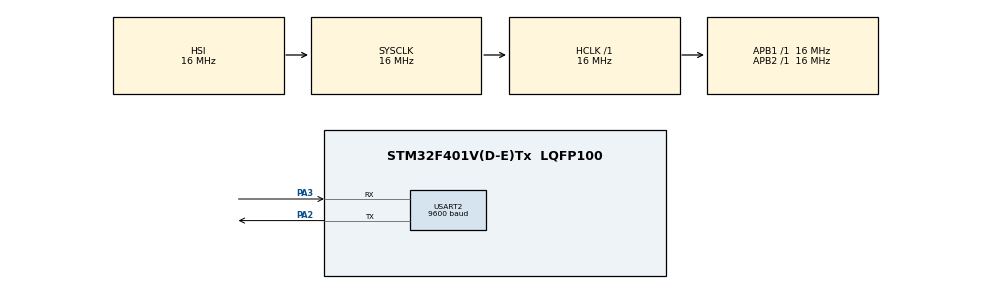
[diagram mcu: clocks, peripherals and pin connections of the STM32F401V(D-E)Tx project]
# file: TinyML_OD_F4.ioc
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Mcu.Family=STM32F4
Mcu.Name=STM32F401V(D-E)Tx
Mcu.Package=LQFP100
NVIC.PriorityGroup=NVIC_PRIORITYGROUP_4
NVIC.USART2_IRQn=true\:0\:0\:false\:false\:true\:true\:true\:true
PA13.Mode=Serial_Wire
PA13.Signal=SYS_JTMS-SWDIO
PA14.Mode=Serial_Wire
PA14.Signal=SYS_JTCK-SWCLK
PA2.Mode=Asynchronous
PA2.Signal=USART2_TX
PA3.Mode=Asynchronous
PA3.Signal=USART2_RX
ProjectManager.HeapSize=0x4000
ProjectManager.StackSize=0x2000
ProjectManager.TargetToolchain=MDK-ARM V5.32
RCC.48MHZClocksFreq_Value=32000000
RCC.AHBFreq_Value=16000000
RCC.APB1Freq_Value=16000000
RCC.APB1TimFreq_Value=16000000
RCC.APB2Freq_Value=16000000
RCC.APB2TimFreq_Value=16000000
RCC.CortexFreq_Value=16000000
RCC.HCLKFreq_Value=16000000
RCC.HSE_VALUE=25000000
RCC.HSI_VALUE=16000000
RCC.LSE_VALUE=32768
RCC.PLLM=8
RCC.PLLN=64
RCC.SYSCLKFreq_VALUE=16000000
RCC.VCOOutputFreq_Value=128000000
STMicroelectronics.X-CUBE-AI.10.0.0.ActivationBufferSizeList=45016
STMicroelectronics.X-CUBE-AI.10.0.0.ActivationBuffers=pool0
STMicroelectronics.X-CUBE-AI.10.0.0.ActivationNames=pool0
STMicroelectronics.X-CUBE-AI.10.0.0.ActivationSizes=AI_OB_MODEL_DATA_ACTIVATION_1_SIZE
STMicroelectronics.X-CUBE-AI.10.0.0.HeapSize=0x4000
STMicroelectronics.X-CUBE-AI.10.0.0.InternalRamActivationBufferMaxSize=AI_OB_MODEL_DATA_ACTIVATIONS_SIZE
STMicroelectronics.X-CUBE-AI.10.0.0.LatestDirectoryUsed-fb2fbbf6d10c69e260894ae3618b915720636bb1a9a1eeecbf556834b52556cf=D\:\\CreateProject\\TinyML_Obstacle Detection\\Ai_Model
STMicroelectronics.X-CUBE-AI.10.0.0.MaximumNumberOfInputLayer=1
STMicroelectronics.X-CUBE-AI.10.0.0.MaximumNumberOfOutputLayer=1
STMicroelectronics.X-CUBE-AI.10.0.0.MaximumSizeOfInputLayer=1
STMicroelectronics.X-CUBE-AI.10.0.0.MaximumSizeOfOutputLayer=1
STMicroelectronics.X-CUBE-AI.10.0.0.ModelActualCompression-fb2fbbf6d10c69e260894ae3618b915720636bb1a9a1eeecbf556834b52556cf=0.0
STMicroelectronics.X-CUBE-AI.10.0.0.ModelCompression-fb2fbbf6d10c69e260894ae3618b915720636bb1a9a1eeecbf556834b52556cf=High
STMicroelectronics.X-CUBE-AI.10.0.0.ModelFlashOccupation-fb2fbbf6d10c69e260894ae3618b915720636bb1a9a1eeecbf556834b52556cf=23744
STMicroelectronics.X-CUBE-AI.10.0.0.ModelHashList=fb2fbbf6d10c69e260894ae3618b915720636bb1a9a1eeecbf556834b52556cf
STMicroelectronics.X-CUBE-AI.10.0.0.ModelKind-fb2fbbf6d10c69e260894ae3618b915720636bb1a9a1eeecbf556834b52556cf=ONNX
STMicroelectronics.X-CUBE-AI.10.0.0.ModelMacc-fb2fbbf6d10c69e260894ae3618b915720636bb1a9a1eeecbf556834b52556cf=296155
STMicroelectronics.X-CUBE-AI.10.0.0.ModelName-fb2fbbf6d10c69e260894ae3618b915720636bb1a9a1eeecbf556834b52556cf=ob_model
STMicroelectronics.X-CUBE-AI.10.0.0.ModelNameList=ob_model
STMicroelectronics.X-CUBE-AI.10.0.0.ModelRamOccupation-fb2fbbf6d10c69e260894ae3618b915720636bb1a9a1eeecbf556834b52556cf=45016
STMicroelectronics.X-CUBE-AI.10.0.0.ModelStructureFile-fb2fbbf6d10c69e260894ae3618b915720636bb1a9a1eeecbf556834b52556cf=D\:\\CreateProject\\TinyML_Obstacle Detection\\Ai_Model\\obstacle_model.onnx
STMicroelectronics.X-CUBE-AI.10.0.0.ModelType-fb2fbbf6d10c69e260894ae3618b915720636bb1a9a1eeecbf556834b52556cf=STM32Cube.AI MCU runtime
STMicroelectronics.X-CUBE-AI.10.0.0.ReadyForCodeGeneration=true
STMicroelectronics.X-CUBE-AI.10.0.0.StackSize=0x2000
STMicroelectronics.X-CUBE-AI.10.0.0.WorkingBufferStartAddrList=0xFFFFFFFF
STMicroelectronics.X-CUBE-AI.10.0.0.XAaCUBEAaAICcArtificialOoIntelligenceJjCore=true
STMicroelectronics.X-CUBE-AI.10.0.0.copyWeightToRam-fb2fbbf6d10c69e260894ae3618b915720636bb1a9a1eeecbf556834b52556cf=false
STMicroelectronics.X-CUBE-AI.10.0.0.customLayerConfigEnabled-fb2fbbf6d10c69e260894ae3618b915720636bb1a9a1eeecbf556834b52556cf=false
STMicroelectronics.X-CUBE-AI.10.0.0.noOnnxIoTranspose-fb2fbbf6d10c69e260894ae3618b915720636bb1a9a1eeecbf556834b52556cf=false
STMicroelectronics.X-CUBE-AI.10.0.0.optimization-fb2fbbf6d10c69e260894ae3618b915720636bb1a9a1eeecbf556834b52556cf=ram
STMicroelectronics.X-CUBE-AI.10.0.0.useInputAllocation-fb2fbbf6d10c69e260894ae3618b915720636bb1a9a1eeecbf556834b52556cf=true
STMicroelectronics.X-CUBE-AI.10.0.0.useOutputAllocation-fb2fbbf6d10c69e260894ae3618b915720636bb1a9a1eeecbf556834b52556cf=true
USART2.BaudRate=9600
USART2.VirtualMode=VM_ASYNC
VP_CRC_VS_CRC.Mode=CRC_Activate
VP_STMicroelectronics.X-CUBE-AI_VS_ArtificialOoIntelligenceJjXAaCUBEAaAI_10.0.0.Mode=ArtificialOoIntelligenceJjXAaCUBEAaAI
board=custom

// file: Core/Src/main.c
/* USER CODE BEGIN Header */
/**
  ******************************************************************************
  * @file           : main.c
  * @brief          : Main program body
  ******************************************************************************
  * @attention
  *
  * Copyright (c) 2026 STMicroelectronics.
  * All rights reserved.
  *
  * This software is licensed under terms that can be found in the LICENSE file
  * in the root directory of this software component.
  * If no LICENSE file comes with this software, it is provided AS-IS.
  *
  ******************************************************************************
  */
/* USER CODE END Header */
#include "main.h"
#include "crc.h"
#include "usart.h"
#include "gpio.h"

/* USER CODE BEGIN Includes */
#include "infer_engine.h"
#include "risk_calc.h"
#include "fsm_controller.h"
#include "sensor_sim.h"
#include <stdio.h>
#include <string.h>
/* USER CODE END Includes */

void SystemClock_Config(void);

/* USER CODE BEGIN 0 */
#define TX_BUFFER_SIZE 300
char tx_buffer[TX_BUFFER_SIZE];
volatile uint8_t tx_flag = 1;

VehicleState_t my_vehicle_state = {0};
uint8_t probability = 0;
uint8_t live_camera_frame[9216];
extern char result_buffer[200];
/* USER CODE END 0 */

int main(void)
{

  /* MCU Configuration--------------------------------------------------------*/

  /* Reset of all peripherals, Initializes the Flash interface and the Systick. */
  HAL_Init();

  /* Configure the system clock */
  SystemClock_Config();

  /* Initialize all configured peripherals */
  MX_GPIO_Init();
  MX_USART2_UART_Init();
  MX_CRC_Init();
  /* USER CODE BEGIN 2 */

  FSM_Init();

  if (InferEngine_Init())
  {
      char err_msg[] = "AI Engine Init Failed!\r\n";
      HAL_UART_Transmit(&huart2, (uint8_t*)err_msg, strlen(err_msg), HAL_MAX_DELAY);
      Error_Handler();
  }

  /* USER CODE END 2 */

  /* Infinite loop */
  /* USER CODE BEGIN WHILE */

  while (1)
  {

		uint8_t prob = SensorSim_CaptureDynamicFrame(live_camera_frame);
		probability = prob;

		FSM_Update(probability, &my_vehicle_state);

		if (tx_flag)
    {
        tx_flag = 0;

				int offset = 0;

				if (result_buffer[0] != '\0')
        {
            offset += snprintf(tx_buffer + offset,
                                (size_t)(TX_BUFFER_SIZE - offset),
                                 "%s", result_buffer);
            if (offset < 0 || offset >= TX_BUFFER_SIZE)
            {
                offset = TX_BUFFER_SIZE - 1;
            }

            result_buffer[0] = '\0';
         }

         offset += snprintf(tx_buffer + offset,
                             (size_t)(TX_BUFFER_SIZE - offset),
                             "Prob: %d%% | TTC: %lu ms | State: %d\r\n",
                             probability,
                             (unsigned long)my_vehicle_state.ttc_ms,
                             FSM_GetState());

        HAL_UART_Transmit_IT(&huart2, (uint8_t*)tx_buffer, strlen(tx_buffer));
    }
		HAL_Delay(1500);

    /* USER CODE END WHILE */

  }
}

void SystemClock_Config(void)
{
  RCC_OscInitTypeDef RCC_OscInitStruct = {0};
  RCC_ClkInitTypeDef RCC_ClkInitStruct = {0};

  /** Configure the main internal regulator output voltage
  */
  __HAL_RCC_PWR_CLK_ENABLE();
  __HAL_PWR_VOLTAGESCALING_CONFIG(PWR_REGULATOR_VOLTAGE_SCALE2);

  /** Initializes the RCC Oscillators according to the specified parameters
  * in the RCC_OscInitTypeDef structure.
  */
  RCC_OscInitStruct.OscillatorType = RCC_OSCILLATORTYPE_HSI;
  RCC_OscInitStruct.HSIState = RCC_HSI_ON;
  RCC_OscInitStruct.HSICalibrationValue = RCC_HSICALIBRATION_DEFAULT;
  RCC_OscInitStruct.PLL.PLLState = RCC_PLL_NONE;
  if (HAL_RCC_OscConfig(&RCC_OscInitStruct) != HAL_OK)
  {
    Error_Handler();
  }

  /** Initializes the CPU, AHB and APB buses clocks
  */
  RCC_ClkInitStruct.ClockType = RCC_CLOCKTYPE_HCLK|RCC_CLOCKTYPE_SYSCLK
                              |RCC_CLOCKTYPE_PCLK1|RCC_CLOCKTYPE_PCLK2;
  RCC_ClkInitStruct.SYSCLKSource = RCC_SYSCLKSOURCE_HSI;
  RCC_ClkInitStruct.AHBCLKDivider = RCC_SYSCLK_DIV1;
  RCC_ClkInitStruct.APB1CLKDivider = RCC_HCLK_DIV1;
  RCC_ClkInitStruct.APB2CLKDivider = RCC_HCLK_DIV1;

  if (HAL_RCC_ClockConfig(&RCC_ClkInitStruct, FLASH_LATENCY_0) != HAL_OK)
  {
    Error_Handler();
  }
}

/* USER CODE BEGIN 4 */
void UART_Print(const char *msg) {
    HAL_UART_Transmit(&huart2, (uint8_t*)msg, strlen(msg), HAL_MAX_DELAY);
}

void HAL_UART_TxCpltCallback(UART_HandleTypeDef *huart)
{
    if (huart->Instance == USART2)
    {
			  tx_flag = 1;
    }
}
int fputc(int ch, FILE *f) {
    HAL_UART_Transmit(&huart2, (uint8_t *)&ch, 1, HAL_MAX_DELAY);
    return ch;
}
/* USER CODE END 4 */

void Error_Handler(void)
{
  __disable_irq();
  while (1)
  {
  }
}
